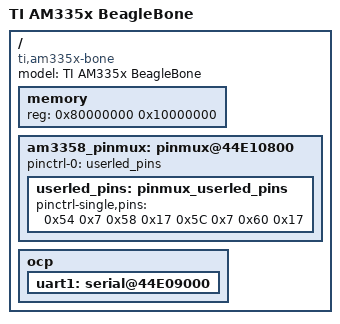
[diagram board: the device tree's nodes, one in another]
/*
 * Copyright (C) 2012 Texas Instruments Incorporated - http://www.ti.com/
 *
 * This program is free software; you can redistribute it and/or modify
 * it under the terms of the GNU General Public License version 2 as
 * published by the Free Software Foundation.
 */
/dts-v1/;

/include/ "am33xx.dtsi"

/ {
	model = "TI AM335x BeagleBone";
	compatible = "ti,am335x-bone", "ti,am33xx";

	memory {
		device_type = "memory";
		reg = <0x80000000 0x10000000>; /* 256 MB */
	};

	am3358_pinmux: pinmux@44E10800 {
		pinctrl-names = "default";
		pinctrl-0 = <&userled_pins>;

		userled_pins: pinmux_userled_pins {
			pinctrl-single,pins = <
				0x54 0x7	/* gpmc_a5.gpio1_21, OUTPUT | MODE7 */
				0x58 0x17	/* gpmc_a6.gpio1_22, OUTPUT_PULLUP | MODE7 */
				0x5C 0x7	/* gpmc_a7.gpio1_23, OUTPUT | MODE7 */
				0x60 0x17	/* gpmc_a8.gpio1_24, OUTPUT_PULLUP | MODE7 */
			>;
		};
	};

	ocp {
		uart1: serial@44E09000 {
			status = "okay";
		};
	};
};
